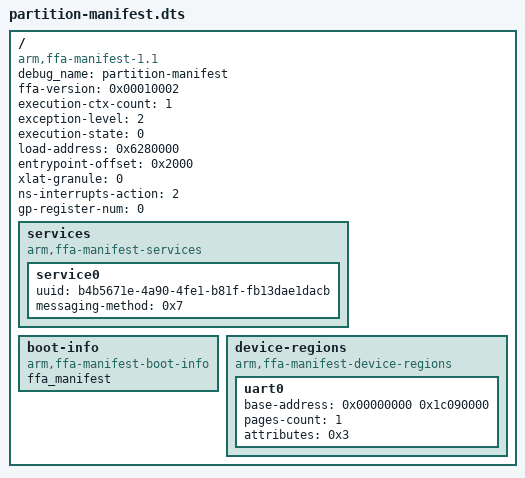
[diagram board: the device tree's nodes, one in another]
/*
 * Copyright 2021 The Hafnium Authors.
 *
 * Use of this source code is governed by a BSD-style
 * license that can be found in the LICENSE file or at
 * https://opensource.org/licenses/BSD-3-Clause.
 */

/dts-v1/;

/ {
	compatible = "arm,ffa-manifest-1.1";
	debug_name = "partition-manifest";

	/* Properties */
	ffa-version = <0x00010002>; /* 31:16 - Major, 15:0 - Minor */
	execution-ctx-count = <1>;
	exception-level = <2>; /* S-EL1 */
	execution-state = <0>; /* AARCH64 */
	load-address = <0x6280000>;
	entrypoint-offset = <0x2000>;
	xlat-granule = <0>; /* 4KiB */
	ns-interrupts-action = <2>; /* Non secure interrupts are signaled. */
	gp-register-num = <0>;

	services {
		compatible = "arm,ffa-manifest-services";

		service0 {
			uuid = "b4b5671e-4a90-4fe1-b81f-fb13dae1dacb";
			messaging-method = <0x7>; /* Direct and indirect requests,
						   * must be non-zero. */
		};
	};

	/* Boot Info */
	boot-info {
		compatible = "arm,ffa-manifest-boot-info";
		ffa_manifest;
	};

	device-regions {
		compatible = "arm,ffa-manifest-device-regions";

		uart0 {
			base-address = <0x00000000 0x1c090000>;
			pages-count = <1>;
			attributes = <0x3>; /* read-write */
		};
	};
};
